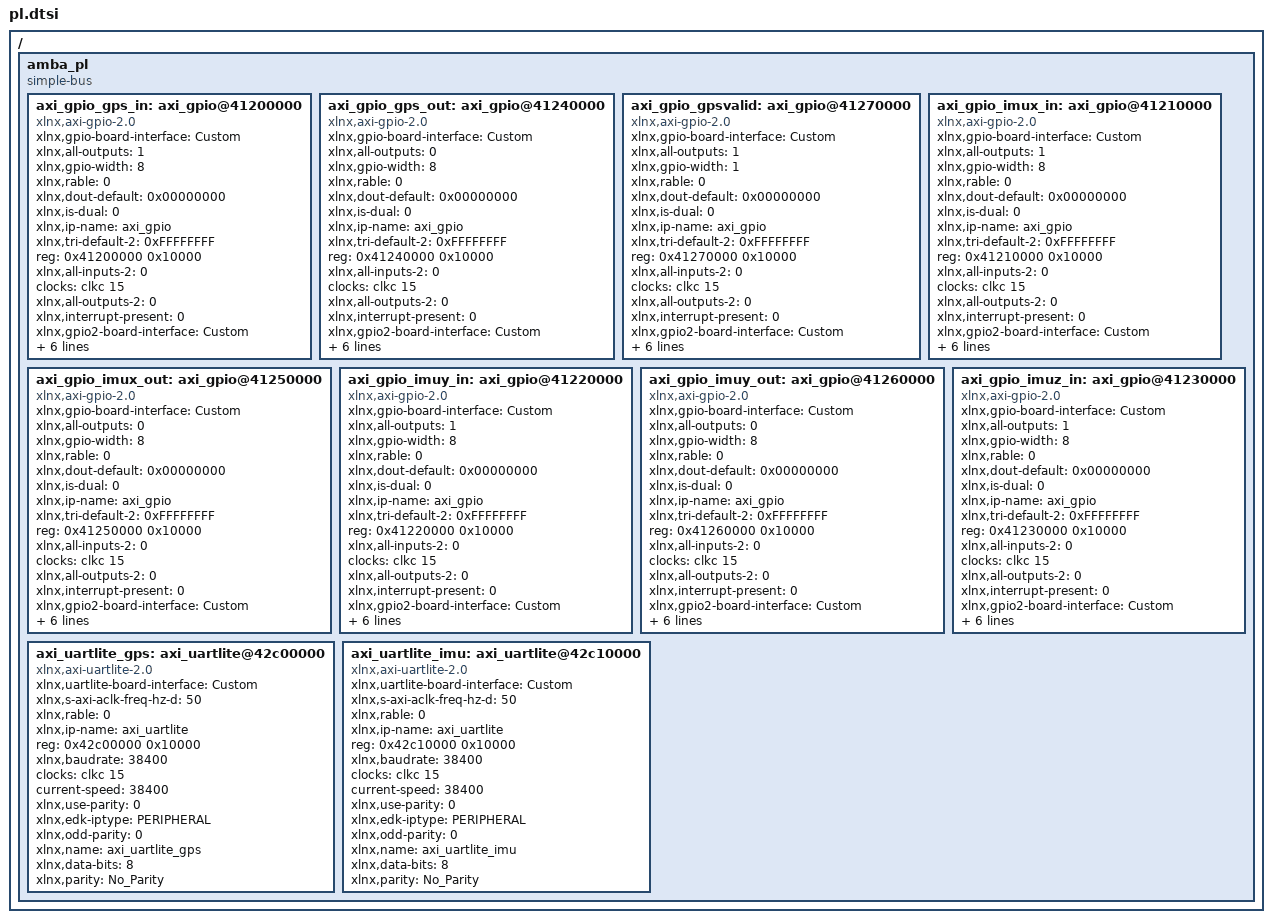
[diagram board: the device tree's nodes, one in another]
/ {
	amba_pl: amba_pl {
		ranges;
		compatible = "simple-bus";
		#address-cells = <1>;
		#size-cells = <1>;
		axi_gpio_gps_in: axi_gpio@41200000 {
			xlnx,gpio-board-interface = "Custom";
			compatible = "xlnx,axi-gpio-2.0" , "xlnx,xps-gpio-1.00.a";
			xlnx,all-outputs = <1>;
			xlnx,gpio-width = <8>;
			xlnx,rable = <0>;
			xlnx,dout-default = <0x00000000>;
			xlnx,is-dual = <0>;
			xlnx,ip-name = "axi_gpio";
			xlnx,tri-default-2 = <0xFFFFFFFF>;
			reg = <0x41200000 0x10000>;
			xlnx,all-inputs-2 = <0>;
			clocks = <&clkc 15>;
			xlnx,all-outputs-2 = <0>;
			xlnx,interrupt-present = <0>;
			xlnx,gpio2-board-interface = "Custom";
			xlnx,edk-iptype = "PERIPHERAL";
			xlnx,dout-default-2 = <0x00000000>;
			xlnx,gpio2-width = <32>;
			status = "okay";
			clock-names = "s_axi_aclk";
			xlnx,tri-default = <0xFFFFFFFF>;
			xlnx,name = "axi_gpio_gps_in";
			xlnx,all-inputs = <0>;
		};
		axi_gpio_gps_out: axi_gpio@41240000 {
			xlnx,gpio-board-interface = "Custom";
			compatible = "xlnx,axi-gpio-2.0" , "xlnx,xps-gpio-1.00.a";
			xlnx,all-outputs = <0>;
			xlnx,gpio-width = <8>;
			xlnx,rable = <0>;
			xlnx,dout-default = <0x00000000>;
			xlnx,is-dual = <0>;
			xlnx,ip-name = "axi_gpio";
			xlnx,tri-default-2 = <0xFFFFFFFF>;
			reg = <0x41240000 0x10000>;
			xlnx,all-inputs-2 = <0>;
			clocks = <&clkc 15>;
			xlnx,all-outputs-2 = <0>;
			xlnx,interrupt-present = <0>;
			xlnx,gpio2-board-interface = "Custom";
			xlnx,edk-iptype = "PERIPHERAL";
			xlnx,dout-default-2 = <0x00000000>;
			xlnx,gpio2-width = <32>;
			status = "okay";
			clock-names = "s_axi_aclk";
			xlnx,tri-default = <0xFFFFFFFF>;
			xlnx,name = "axi_gpio_gps_out";
			xlnx,all-inputs = <1>;
		};
		axi_gpio_gpsvalid: axi_gpio@41270000 {
			xlnx,gpio-board-interface = "Custom";
			compatible = "xlnx,axi-gpio-2.0" , "xlnx,xps-gpio-1.00.a";
			xlnx,all-outputs = <1>;
			xlnx,gpio-width = <1>;
			xlnx,rable = <0>;
			xlnx,dout-default = <0x00000000>;
			xlnx,is-dual = <0>;
			xlnx,ip-name = "axi_gpio";
			xlnx,tri-default-2 = <0xFFFFFFFF>;
			reg = <0x41270000 0x10000>;
			xlnx,all-inputs-2 = <0>;
			clocks = <&clkc 15>;
			xlnx,all-outputs-2 = <0>;
			xlnx,interrupt-present = <0>;
			xlnx,gpio2-board-interface = "Custom";
			xlnx,edk-iptype = "PERIPHERAL";
			xlnx,dout-default-2 = <0x00000000>;
			xlnx,gpio2-width = <32>;
			status = "okay";
			clock-names = "s_axi_aclk";
			xlnx,tri-default = <0xFFFFFFFF>;
			xlnx,name = "axi_gpio_gpsvalid";
			xlnx,all-inputs = <0>;
		};
		axi_gpio_imux_in: axi_gpio@41210000 {
			xlnx,gpio-board-interface = "Custom";
			compatible = "xlnx,axi-gpio-2.0" , "xlnx,xps-gpio-1.00.a";
			xlnx,all-outputs = <1>;
			xlnx,gpio-width = <8>;
			xlnx,rable = <0>;
			xlnx,dout-default = <0x00000000>;
			xlnx,is-dual = <0>;
			xlnx,ip-name = "axi_gpio";
			xlnx,tri-default-2 = <0xFFFFFFFF>;
			reg = <0x41210000 0x10000>;
			xlnx,all-inputs-2 = <0>;
			clocks = <&clkc 15>;
			xlnx,all-outputs-2 = <0>;
			xlnx,interrupt-present = <0>;
			xlnx,gpio2-board-interface = "Custom";
			xlnx,edk-iptype = "PERIPHERAL";
			xlnx,dout-default-2 = <0x00000000>;
			xlnx,gpio2-width = <32>;
			status = "okay";
			clock-names = "s_axi_aclk";
			xlnx,tri-default = <0xFFFFFFFF>;
			xlnx,name = "axi_gpio_imux_in";
			xlnx,all-inputs = <0>;
		};
		axi_gpio_imux_out: axi_gpio@41250000 {
			xlnx,gpio-board-interface = "Custom";
			compatible = "xlnx,axi-gpio-2.0" , "xlnx,xps-gpio-1.00.a";
			xlnx,all-outputs = <0>;
			xlnx,gpio-width = <8>;
			xlnx,rable = <0>;
			xlnx,dout-default = <0x00000000>;
			xlnx,is-dual = <0>;
			xlnx,ip-name = "axi_gpio";
			xlnx,tri-default-2 = <0xFFFFFFFF>;
			reg = <0x41250000 0x10000>;
			xlnx,all-inputs-2 = <0>;
			clocks = <&clkc 15>;
			xlnx,all-outputs-2 = <0>;
			xlnx,interrupt-present = <0>;
			xlnx,gpio2-board-interface = "Custom";
			xlnx,edk-iptype = "PERIPHERAL";
			xlnx,dout-default-2 = <0x00000000>;
			xlnx,gpio2-width = <32>;
			status = "okay";
			clock-names = "s_axi_aclk";
			xlnx,tri-default = <0xFFFFFFFF>;
			xlnx,name = "axi_gpio_imux_out";
			xlnx,all-inputs = <1>;
		};
		axi_gpio_imuy_in: axi_gpio@41220000 {
			xlnx,gpio-board-interface = "Custom";
			compatible = "xlnx,axi-gpio-2.0" , "xlnx,xps-gpio-1.00.a";
			xlnx,all-outputs = <1>;
			xlnx,gpio-width = <8>;
			xlnx,rable = <0>;
			xlnx,dout-default = <0x00000000>;
			xlnx,is-dual = <0>;
			xlnx,ip-name = "axi_gpio";
			xlnx,tri-default-2 = <0xFFFFFFFF>;
			reg = <0x41220000 0x10000>;
			xlnx,all-inputs-2 = <0>;
			clocks = <&clkc 15>;
			xlnx,all-outputs-2 = <0>;
			xlnx,interrupt-present = <0>;
			xlnx,gpio2-board-interface = "Custom";
			xlnx,edk-iptype = "PERIPHERAL";
			xlnx,dout-default-2 = <0x00000000>;
			xlnx,gpio2-width = <32>;
			status = "okay";
			clock-names = "s_axi_aclk";
			xlnx,tri-default = <0xFFFFFFFF>;
			xlnx,name = "axi_gpio_imuy_in";
			xlnx,all-inputs = <0>;
		};
		axi_gpio_imuy_out: axi_gpio@41260000 {
			xlnx,gpio-board-interface = "Custom";
			compatible = "xlnx,axi-gpio-2.0" , "xlnx,xps-gpio-1.00.a";
			xlnx,all-outputs = <0>;
			xlnx,gpio-width = <8>;
			xlnx,rable = <0>;
			xlnx,dout-default = <0x00000000>;
			xlnx,is-dual = <0>;
			xlnx,ip-name = "axi_gpio";
			xlnx,tri-default-2 = <0xFFFFFFFF>;
			reg = <0x41260000 0x10000>;
			xlnx,all-inputs-2 = <0>;
			clocks = <&clkc 15>;
			xlnx,all-outputs-2 = <0>;
			xlnx,interrupt-present = <0>;
			xlnx,gpio2-board-interface = "Custom";
			xlnx,edk-iptype = "PERIPHERAL";
			xlnx,dout-default-2 = <0x00000000>;
			xlnx,gpio2-width = <32>;
			status = "okay";
			clock-names = "s_axi_aclk";
			xlnx,tri-default = <0xFFFFFFFF>;
			xlnx,name = "axi_gpio_imuy_out";
			xlnx,all-inputs = <1>;
		};
		axi_gpio_imuz_in: axi_gpio@41230000 {
			xlnx,gpio-board-interface = "Custom";
			compatible = "xlnx,axi-gpio-2.0" , "xlnx,xps-gpio-1.00.a";
			xlnx,all-outputs = <1>;
			xlnx,gpio-width = <8>;
			xlnx,rable = <0>;
			xlnx,dout-default = <0x00000000>;
			xlnx,is-dual = <0>;
			xlnx,ip-name = "axi_gpio";
			xlnx,tri-default-2 = <0xFFFFFFFF>;
			reg = <0x41230000 0x10000>;
			xlnx,all-inputs-2 = <0>;
			clocks = <&clkc 15>;
			xlnx,all-outputs-2 = <0>;
			xlnx,interrupt-present = <0>;
			xlnx,gpio2-board-interface = "Custom";
			xlnx,edk-iptype = "PERIPHERAL";
			xlnx,dout-default-2 = <0x00000000>;
			xlnx,gpio2-width = <32>;
			status = "okay";
			clock-names = "s_axi_aclk";
			xlnx,tri-default = <0xFFFFFFFF>;
			xlnx,name = "axi_gpio_imuz_in";
			xlnx,all-inputs = <0>;
		};
		axi_uartlite_gps: axi_uartlite@42c00000 {
			compatible = "xlnx,axi-uartlite-2.0" , "xlnx,xps-uartlite-1.00.a";
			xlnx,uartlite-board-interface = "Custom";
			xlnx,s-axi-aclk-freq-hz-d = <50>;
			xlnx,rable = <0>;
			xlnx,ip-name = "axi_uartlite";
			reg = <0x42c00000 0x10000>;
			xlnx,baudrate = <38400>;
			clocks = <&clkc 15>;
			current-speed = <38400>;
			xlnx,use-parity = <0>;
			xlnx,edk-iptype = "PERIPHERAL";
			xlnx,odd-parity = <0>;
			status = "okay";
			clock-names = "s_axi_aclk";
			xlnx,name = "axi_uartlite_gps";
			xlnx,data-bits = <8>;
			xlnx,parity = "No_Parity";
		};
		axi_uartlite_imu: axi_uartlite@42c10000 {
			compatible = "xlnx,axi-uartlite-2.0" , "xlnx,xps-uartlite-1.00.a";
			xlnx,uartlite-board-interface = "Custom";
			xlnx,s-axi-aclk-freq-hz-d = <50>;
			xlnx,rable = <0>;
			xlnx,ip-name = "axi_uartlite";
			reg = <0x42c10000 0x10000>;
			xlnx,baudrate = <38400>;
			clocks = <&clkc 15>;
			current-speed = <38400>;
			xlnx,use-parity = <0>;
			xlnx,edk-iptype = "PERIPHERAL";
			xlnx,odd-parity = <0>;
			status = "okay";
			clock-names = "s_axi_aclk";
			xlnx,name = "axi_uartlite_imu";
			xlnx,data-bits = <8>;
			xlnx,parity = "No_Parity";
		};
	};
};
